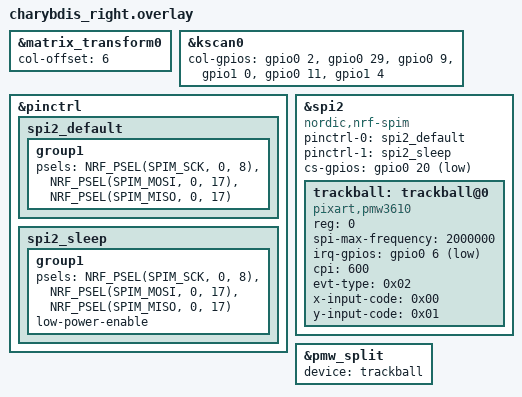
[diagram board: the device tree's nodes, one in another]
/*
 * Copyright (c) 2020 ZMK Contributors
 *
 * SPDX-License-Identifier: MIT
 */
 
#include "charybdis.dtsi"

&matrix_transform0 {
    col-offset = <6>;
};

&kscan0 {
    col-gpios
        = <&gpio0 2 (GPIO_ACTIVE_HIGH | GPIO_PULL_DOWN)>
        , <&gpio0 29 (GPIO_ACTIVE_HIGH | GPIO_PULL_DOWN)>
        , <&gpio0 9 (GPIO_ACTIVE_HIGH | GPIO_PULL_DOWN)>
        , <&gpio1 0 (GPIO_ACTIVE_HIGH | GPIO_PULL_DOWN)>
        , <&gpio0 11 (GPIO_ACTIVE_HIGH | GPIO_PULL_DOWN)>
        , <&gpio1 4 (GPIO_ACTIVE_HIGH | GPIO_PULL_DOWN)>
        ;
};

&pinctrl {
    spi2_default: spi2_default {
        group1 {
            psels = <NRF_PSEL(SPIM_SCK, 0, 8)>,   // SCK на pin 0.08
                    <NRF_PSEL(SPIM_MOSI, 0, 17)>, // MOSI на pin 0.17
                    <NRF_PSEL(SPIM_MISO, 0, 17)>; // MISO на pin 0.17
        };
    };
    
    spi2_sleep: spi2_sleep {
        group1 {
            psels = <NRF_PSEL(SPIM_SCK, 0, 8)>,
                    <NRF_PSEL(SPIM_MOSI, 0, 17)>,
                    <NRF_PSEL(SPIM_MISO, 0, 17)>;
            low-power-enable;
        };
    };
};

&spi2 {
    status = "okay";
    compatible = "nordic,nrf-spim";
    pinctrl-0 = <&spi2_default>;
    pinctrl-1 = <&spi2_sleep>;
    pinctrl-names = "default", "sleep";
    cs-gpios = <&gpio0 20 GPIO_ACTIVE_LOW>;
    
    trackball: trackball@0 {
        status = "okay";
        compatible = "pixart,pmw3610";
        reg = <0>;
        spi-max-frequency = <2000000>;
        irq-gpios = <&gpio0 6 (GPIO_ACTIVE_LOW | GPIO_PULL_UP)>;
        cpi = <600>;
        evt-type = <0x02>;  // INPUT_EV_REL
        x-input-code = <0x00>;  // INPUT_REL_X
        y-input-code = <0x01>;  // INPUT_REL_Y
    };
};

&pmw_split {
    device = <&trackball>;
};
